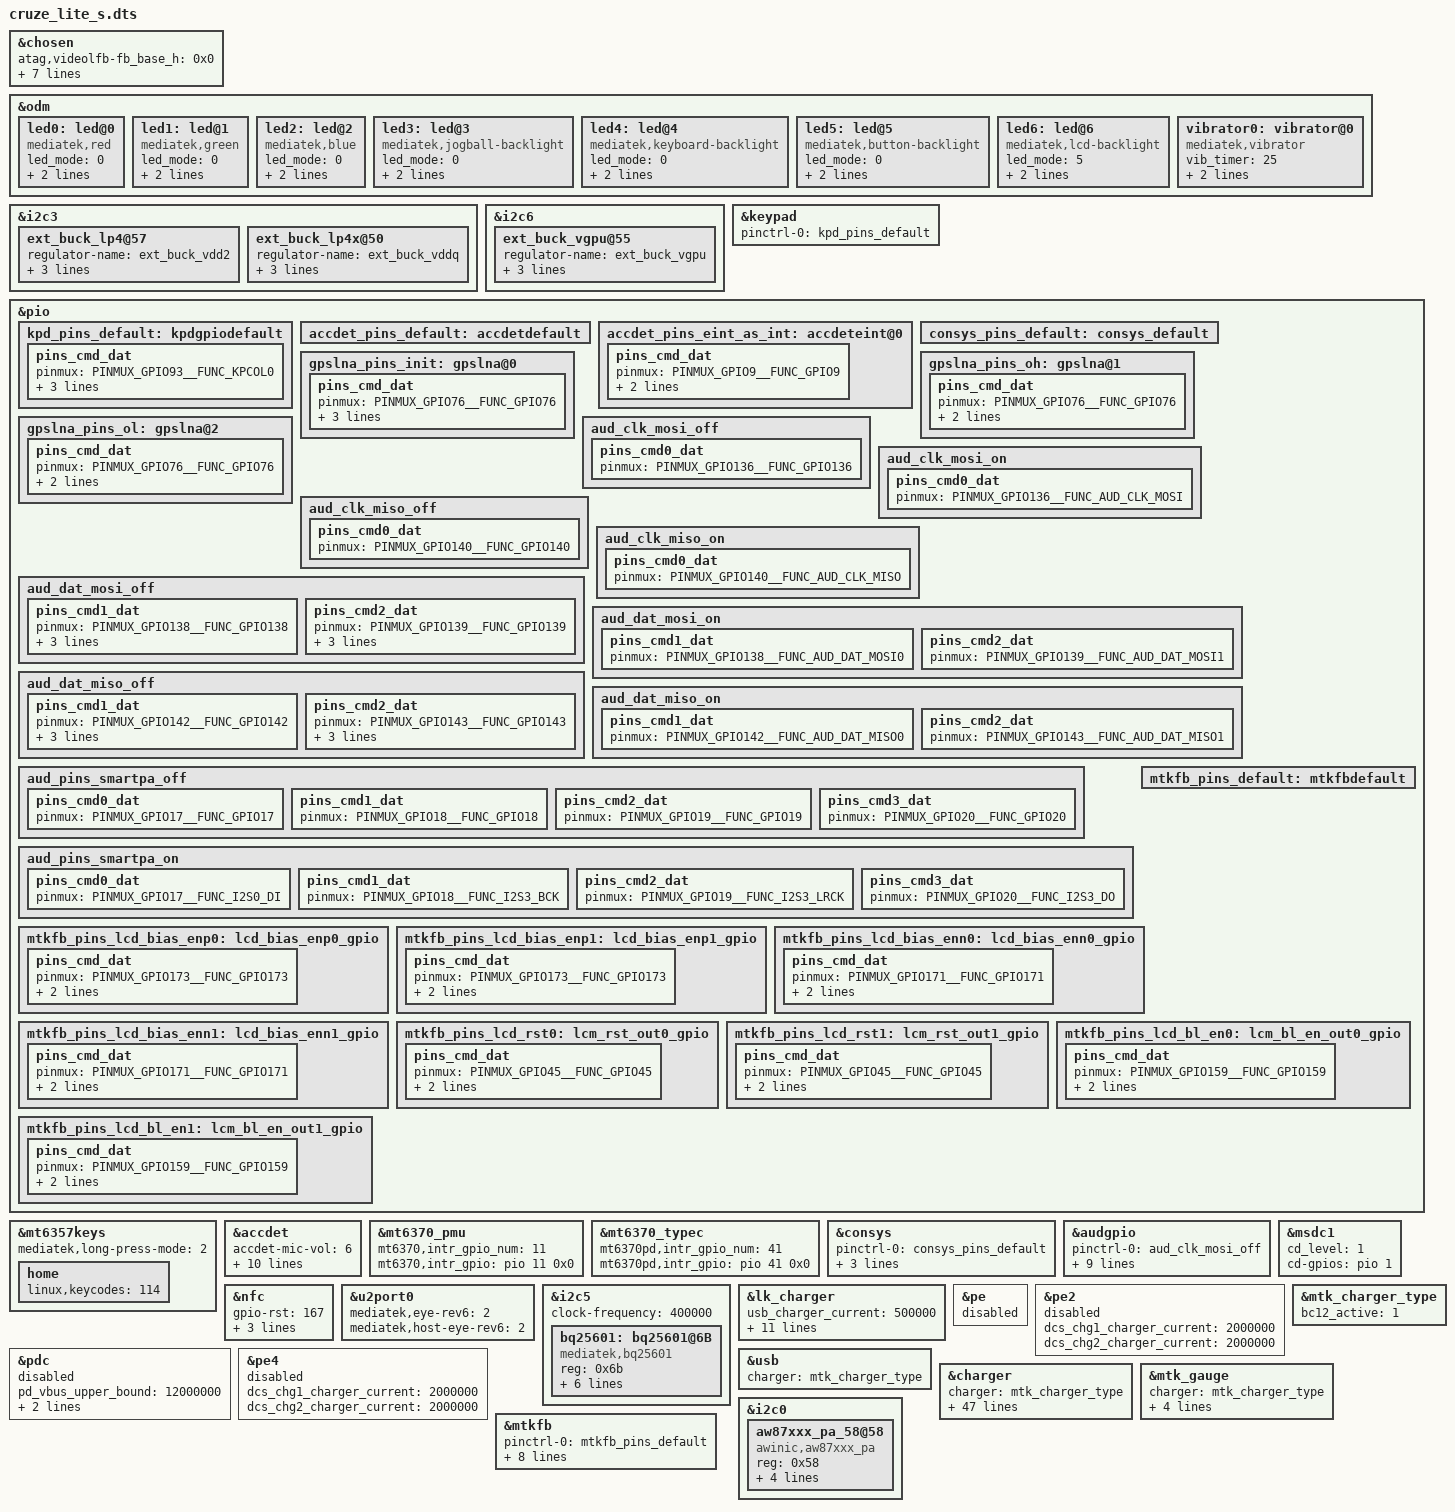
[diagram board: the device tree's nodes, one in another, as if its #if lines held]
// SPDX-License-Identifier: GPL-2.0+

#include <dt-bindings/interrupt-controller/arm-gic.h>
#include <dt-bindings/interrupt-controller/irq.h>
#include <dt-bindings/pinctrl/mt6761-pinfunc.h>
#include <dt-bindings/mmc/mt6761-msdc.h>
#include <dt-bindings/clock/mt6761-clk.h>

/dts-v1/;
/plugin/;

/* chosen */
&chosen {

	/* fpga may has no lk, we need to specify display info here */
	/* fb buffer is reserved using this dts by memory node above */
	atag,videolfb-fb_base_h = <0x0>;
	atag,videolfb-fb_base_l = <0x5e605000>;
	atag,videolfb-islcmfound = <1>;
	/* because no lk, so lcm is not inited */
	atag,videolfb-islcm_inited = <0>;
	atag,videolfb-fps= <6000>;
	atag,videolfb-vramSize= <0x017bb000>;
	atag,videolfb-lcmname= "nt35521_hd_dsi_vdo_truly_rt5081_drv";
};

&odm {
	led0:led@0 {
		compatible = "mediatek,red";
		led_mode = <0>;
		data = <1>;
		pwm_config = <0 0 0 0 0>;
	};
	led1:led@1 {
		compatible = "mediatek,green";
		led_mode = <0>;
		data = <1>;
		pwm_config = <0 0 0 0 0>;
	};
	led2:led@2 {
		compatible = "mediatek,blue";
		led_mode = <0>;
		data = <1>;
		pwm_config = <0 0 0 0 0>;
	};
	led3:led@3 {
		compatible = "mediatek,jogball-backlight";
		led_mode = <0>;
		data = <1>;
		pwm_config = <0 0 0 0 0>;
	};
	led4:led@4 {
		compatible = "mediatek,keyboard-backlight";
		led_mode = <0>;
		data = <1>;
		pwm_config = <0 0 0 0 0>;
	};
	led5:led@5 {
		compatible = "mediatek,button-backlight";
		led_mode = <0>;
		data = <1>;
		pwm_config = <0 0 0 0 0>;
	};
	led6:led@6 {
		compatible = "mediatek,lcd-backlight";
		led_mode = <5>;
		data = <1>;
		pwm_config = <0 3 0 0 0>;
	};
	vibrator0:vibrator@0 {
		compatible = "mediatek,vibrator";
		vib_timer = <25>;
		vib_limit = <9>;
		vib_vol= <9>;
	};
};

/* Begin del by jin.wang for task 11466469 at 2021-09-02 */
/* End del by jin.wang */

&i2c3 {
	ext_buck_lp4@57 {
		regulator-name ="ext_buck_vdd2";
		regulator-min-microvolt = <300000>;
		regulator-max-microvolt = <1300000>;
		vsel_pin = <0>;
	};

	ext_buck_lp4x@50 {
		regulator-name ="ext_buck_vddq";
		regulator-min-microvolt = <300000>;
		regulator-max-microvolt = <1300000>;
		vsel_pin = <1>;
	};
};

&i2c6 {
	ext_buck_vgpu@55 {
		regulator-name ="ext_buck_vgpu";
		regulator-min-microvolt = <300000>;
		regulator-max-microvolt = <1300000>;
		vsel_pin = <2>;
	};
};

&keypad {
	pinctrl-names = "default";
	pinctrl-0 = <&kpd_pins_default>;
};

&pio {
	kpd_pins_default: kpdgpiodefault {
		pins_cmd_dat {
			pinmux = <PINMUX_GPIO93__FUNC_KPCOL0>;
			bias-pull-up = <MTK_PUPD_SET_R1R0_10>;
			output-low;
			input-schmitt-enable;
		};
	};
};
/*BEGIN Add by peisong.cao for KEYCODE_VOLUME_DOWN 114*/
&mt6357keys {
#if defined(TARGET_BUILD_MMITEST) || defined(TARGET_BUILD_CERTIFICATION) || defined(TARGET_BUILD_GCF)
     mediatek,long-press-mode = <2>;
#else
     mediatek,long-press-mode = <1>;
#endif
		home {
			linux,keycodes = <114>;
		};
};
/*END Add by peisong.cao for KEYCODE_VOLUME_DOWN 114*/

&accdet {
	accdet-mic-vol = <6>;
	headset-mode-setting = <0x500 0x500 1 0x1f0 0x800 0x800 0x20 0x44>;
	accdet-plugout-debounce = <1>;
	accdet-mic-mode = <1>;
	headset-eint-level-pol = <8>;
	headset-three-key-threshold = <0 80 220 400>;
	headset-three-key-threshold-CDD = <0 121 192 600>;
	headset-four-key-threshold = <0 58 121 192 400>;
	pinctrl-names = "default", "state_eint_as_int";
	pinctrl-0 = <&accdet_pins_default>;
	pinctrl-1 = <&accdet_pins_eint_as_int>;
	status = "okay";
};
&pio {
	accdet_pins_default: accdetdefault {
	};
	accdet_pins_eint_as_int: accdeteint@0 {
		pins_cmd_dat {
			pinmux = <PINMUX_GPIO9__FUNC_GPIO9>;
			slew-rate = <0>;
			bias-disable;
		};
	};
};

&mt6370_pmu {
	mt6370,intr_gpio_num = <11>; /* direct defined GPIO num */
	mt6370,intr_gpio = <&pio 11 0x0>;
};

/* Begin del by jin.wang for task 11466469 at 2021-09-02 */

#if 0
&i2c3 {
	rt9465@4b {
		compatible = "richtek,rt9465";
		reg = <0x4b>;
		status = "okay";
		rt,en_gpio_num = <176>;
		rt,en_gpio = <&pio 176 0x0>;
		rt,intr_gpio_num = <23>; /* direct defined GPIO num */
		rt,intr_gpio = <&pio 23 0x0>;
		interrupt-names = "wdtmri";
		charger_name = "secondary_chg";
		ichg = <1500000>; /* uA */
		mivr = <4500000>; /* uV */
		cv = <4550000>; /* uV */
		ieoc = <700000>; /* uA */
		safety_timer = <12>; /* hour */
		en_st; /* safety timer */
		/* en_te; */
		en_wdt;
	};
};
#endif
/* End del by jin.wang */

&mt6370_typec {
	mt6370pd,intr_gpio_num = <41>; /* direct defined GPIO num */
	mt6370pd,intr_gpio = <&pio 41 0x0>;
};
//Begin modified by qianbo.pan for GNSS task 11475215 on 2021/08/29
/* CONSYS GPIO standardization */
&pio {
	consys_pins_default: consys_default {
	};
	gpslna_pins_init: gpslna@0 {
		pins_cmd_dat {
			pinmux = <PINMUX_GPIO76__FUNC_GPIO76>;
			slew-rate = <0>;
			bias-disable;
			output-low;
		};
	};
	gpslna_pins_oh: gpslna@1 {
		pins_cmd_dat {
			pinmux = <PINMUX_GPIO76__FUNC_GPIO76>;
			slew-rate = <1>;
			output-high;
		};
	};
	gpslna_pins_ol: gpslna@2 {
		pins_cmd_dat {
			pinmux = <PINMUX_GPIO76__FUNC_GPIO76>;
			slew-rate = <1>;
			output-low;
		};
	};
};
&consys {
	pinctrl-names = "default", "gps_lna_state_init",
		"gps_lna_state_oh", "gps_lna_state_ol";
	pinctrl-0 = <&consys_pins_default>;
	pinctrl-1 = <&gpslna_pins_init>;
	pinctrl-2 = <&gpslna_pins_oh>;
	pinctrl-3 = <&gpslna_pins_ol>;
	status = "okay";
};
/* CONSYS end */
//End modified by qianbo.pan for GNSS task 11475215 on 2021/08/29
/* AUDIO GPIO standardization */
&audgpio {
	pinctrl-names = "aud_clk_mosi_off",
			"aud_clk_mosi_on",
			"aud_clk_miso_off",
			"aud_clk_miso_on",
			"aud_dat_mosi_off",
			"aud_dat_mosi_on",
			"aud_dat_miso_off",
			"aud_dat_miso_on",
			"aud_smartpa_off",
			"aud_smartpa_on";
	pinctrl-0 = <&aud_clk_mosi_off>;
	pinctrl-1 = <&aud_clk_mosi_on>;
	pinctrl-2 = <&aud_clk_miso_off>;
	pinctrl-3 = <&aud_clk_miso_on>;
	pinctrl-4 = <&aud_dat_mosi_off>;
	pinctrl-5 = <&aud_dat_mosi_on>;
	pinctrl-6 = <&aud_dat_miso_off>;
	pinctrl-7 = <&aud_dat_miso_on>;
	pinctrl-8 = <&aud_pins_smartpa_off>;
	pinctrl-9 = <&aud_pins_smartpa_on>;
	status = "okay";
};

&pio {
	aud_clk_mosi_off: aud_clk_mosi_off {
		pins_cmd0_dat {
			pinmux = <PINMUX_GPIO136__FUNC_GPIO136>;
		};
	};

	aud_clk_mosi_on: aud_clk_mosi_on {
		pins_cmd0_dat {
			pinmux = <PINMUX_GPIO136__FUNC_AUD_CLK_MOSI>;
		};
	};

	aud_clk_miso_off: aud_clk_miso_off {
		pins_cmd0_dat {
			pinmux = <PINMUX_GPIO140__FUNC_GPIO140>;
		};
	};

	aud_clk_miso_on: aud_clk_miso_on {
		pins_cmd0_dat {
			pinmux = <PINMUX_GPIO140__FUNC_AUD_CLK_MISO>;
		};
	};

	aud_dat_mosi_off: aud_dat_mosi_off {
		pins_cmd1_dat {
			pinmux = <PINMUX_GPIO138__FUNC_GPIO138>;
			input-enable;
			slew-rate = <0>;
			bias-disable;
		};
		pins_cmd2_dat {
			pinmux = <PINMUX_GPIO139__FUNC_GPIO139>;
			input-enable;
			slew-rate = <0>;
			bias-disable;
		};
	};

	aud_dat_mosi_on: aud_dat_mosi_on {
		pins_cmd1_dat {
			pinmux = <PINMUX_GPIO138__FUNC_AUD_DAT_MOSI0>;
		};
		pins_cmd2_dat {
			pinmux = <PINMUX_GPIO139__FUNC_AUD_DAT_MOSI1>;
		};
	};

	aud_dat_miso_off: aud_dat_miso_off {
		pins_cmd1_dat {
			pinmux = <PINMUX_GPIO142__FUNC_GPIO142>;
			input-enable;
			slew-rate = <0>;
			bias-disable;
		};
		pins_cmd2_dat {
			pinmux = <PINMUX_GPIO143__FUNC_GPIO143>;
			input-enable;
			slew-rate = <0>;
			bias-disable;
		};
	};

	aud_dat_miso_on: aud_dat_miso_on {
		pins_cmd1_dat {
			pinmux = <PINMUX_GPIO142__FUNC_AUD_DAT_MISO0>;
		};
		pins_cmd2_dat {
			pinmux = <PINMUX_GPIO143__FUNC_AUD_DAT_MISO1>;
		};
	};

	aud_pins_smartpa_off: aud_pins_smartpa_off {
		pins_cmd0_dat {
			pinmux = <PINMUX_GPIO17__FUNC_GPIO17>;
		};
		pins_cmd1_dat {
			pinmux = <PINMUX_GPIO18__FUNC_GPIO18>;
		};
		pins_cmd2_dat {
			pinmux = <PINMUX_GPIO19__FUNC_GPIO19>;
		};
		pins_cmd3_dat {
			pinmux = <PINMUX_GPIO20__FUNC_GPIO20>;
		};
	};

	aud_pins_smartpa_on: aud_pins_smartpa_on {
		pins_cmd0_dat {
			pinmux = <PINMUX_GPIO17__FUNC_I2S0_DI>;
		};
		pins_cmd1_dat {
			pinmux = <PINMUX_GPIO18__FUNC_I2S3_BCK>;
		};
		pins_cmd2_dat {
			pinmux = <PINMUX_GPIO19__FUNC_I2S3_LRCK>;
		};
		pins_cmd3_dat {
			pinmux = <PINMUX_GPIO20__FUNC_I2S3_DO>;
		};
	};
};
/* AUDIO end */
/*Begin add by YuBin for sdcard det*/
&msdc1 {
       cd_level = /bits/ 8 <1>;
       cd-gpios = <&pio 1 0>;
};
/*End add by YuBin for sdcard det*/
//Begin add by na.long for task11386747 porting  on 2021/07/27
&nfc {
	gpio-rst = <167>;
	gpio-rst-std = <&pio 167 0x0>;
	gpio-irq = <9>;
	gpio-irq-std = <&pio 9 0x0>;
};
//End add by na.long for task11386747 porting  on 2021/07/27

&u2port0 {
	mediatek,eye-rev6 = <2>; /* 0~3 */
	mediatek,host-eye-rev6 = <2>; /* 0~3 */
};
/* End add by jin.wang */

/* Begin add by jin.wang for task 2064 at 2021-10-25 */
&i2c5 {
	#address-cells = <1>;
	#size-cells = <0>;
	clock-frequency = <400000>;

	bq25601:bq25601@6B {
		compatible = "mediatek,bq25601";
		reg = <0x6b>;
		id = <0x5>;
		status = "okay";
		charger_name = "primary_chg";
		alias_name = "bq25601";
		bq25601,en_gpio = <&pio 165 0x0>;
		bq25601,intr_gpio = <&pio 12 0x0>;
		eint_name = "bq25601_intr";
	};
};
/* End add by jin.wang */

/* Begin added by jin.wang for task 11466469 at 2021-09-02 */
&lk_charger {
	/* charging current */
	usb_charger_current = <500000>;
	ac_charger_current = <500000>;
	ac_charger_input_current = <500000>;
	non_std_ac_charger_current = <500000>;
	charging_host_charger_current = <500000>;
	ta_ac_charger_current = <500000>;
	pd_charger_current = <500000>;
	max_charger_voltage = <6500000>;

	/* battery temperature protection */
	temp_t4_threshold = <54>;
	temp_t3_threshold = <45>;
	temp_t1_threshold = <6>;
	temp_t0_threshold = <1>;
};

&pe {
	status = "disabled";
};

&pe2 {
	status = "disabled";
	dcs_chg1_charger_current = <2000000>;
	dcs_chg2_charger_current = <2000000>;
};

&pdc {
	status = "disabled";
	pd_vbus_upper_bound = <12000000>;
	dcs_chg1_charger_current = <2000000>;
	dcs_chg2_charger_current = <2000000>;
};

&pe4 {
	status = "disabled";
	dcs_chg1_charger_current = <2000000>;
	dcs_chg2_charger_current = <2000000>;
};

&mtk_charger_type {
	bc12_active = <1>;
};

&usb{
	charger = <&mtk_charger_type>;
};

/* Begin mod by jin.wang for jira 2064 at 2021-10-26 */
&charger {
    charger = <&mtk_charger_type>;
    charger_configuration= <0>;

    /* common */
    power_path_support;
    enable_dynamic_mivr;
    battery_cv = <4400000>;

    /* charging current */
    usb_charger_current_suspend = <0>;
    usb_charger_current_unconfigured = <70000>;
    usb_charger_current_configured = <500000>;
    usb_charger_current = <500000>;
    ac_charger_current = <2000000>;
    ac_charger_input_current = <2100000>;
    non_std_ac_charger_current = <500000>;
    charging_host_charger_current = <1300000>;

    /* sw jeita */
    enable_sw_jeita;
    jeita_temp_above_t4_cv = <4100000>;
    jeita_temp_t3_to_t4_cv = <4100000>;
    jeita_temp_t2_to_t3_cv = <4400000>;
    jeita_temp_t1_to_t2_cv = <4400000>;
    jeita_temp_t0_to_t1_cv = <4400000>;
    jeita_temp_below_t0_cv = <4400000>;
    temp_t4_thres = <55>;
    temp_t4_thres_minus_x_degree = <51>;
    temp_t3_thres = <42>;
    temp_t3_thres_minus_x_degree = <41>;
    temp_t2_thres = <11>;
    temp_t2_thres_plus_x_degree = <12>;
    temp_t1_thres = <6>;
    temp_t1_thres_plus_x_degree = <7>;
    temp_t0_thres = <0>;
    temp_t0_thres_plus_x_degree = <1>;
    temp_neg_10_thres = <2>;

    jeita_temp_above_t4_current = <0>;
    jeita_temp_t3_to_t4_current = <1500000>;
    jeita_temp_t2_to_t3_current = <3600000>;
    jeita_temp_t1_to_t2_current = <950000>;
    jeita_temp_t0_to_t1_current = <950000>;
    jeita_temp_below_t0_current = <0>;

    /* battery temperature protection */
    enable_min_charge_temp;
    min_charge_temp = <1>;
    min_charge_temp_plus_x_degree = <2>;
    max_charge_temp = <53>;
    max_charge_temp_minus_x_degree = <51>;

    enable_step_chg;
    step_chg_vbat = <4300000>;
    step_chg_vbat_hysteresis = <100000>;
    setp_chg_current = <2800000>;

    vbat_cable_imp_threshold = <3300000>; /* uV */
    car_tune_value_sy6970qcc = <1020>;
};
/* End mod by jin.wang */

#include <dt-bindings/iio/mt635x-auxadc.h>
&mtk_gauge {
	charger = <&mtk_charger_type>;
	io-channels = <&pmic_auxadc AUXADC_BAT_TEMP>,
			<&pmic_auxadc AUXADC_BATADC>,
			<&pmic_auxadc AUXADC_VBIF>,
			<&pmic_auxadc AUXADC_IMP>,
			<&auxadc 2>;
	io-channel-names = "pmic_battery_temp",
			"pmic_battery_voltage",
			"pmic_bif_voltage",
			"pmic_ptim_voltage",
			"battery_id";
};
/* End added by jin.wang */

&i2c0 {
	/* AWINIC AW87359 Smart K PA */
	aw87xxx_pa_58@58 {
		compatible = "awinic,aw87xxx_pa";
		reg = <0x58>;
		pa-channel = < 0 >;
		monitor-flag = <0>; //1=enable
		monitor-timer-val = <3000>; //time interval, ms
		monitor-timer-count-max = <5>; //counts for average
		status = "okay";
	};
	/* AWINIC AW87359 Smart K PA End */
};

/* Begin added by jin.wang for task 11466469 at 2021-09-02 */
#include "bat_setting/cruze_lite_s/cruze_lite_s_mt6761_battery_prop_ext.dtsi"
/* End added by jin.wang for task 11466469 at 2021-09-02 */

#include <cruze_lite_s/cust.dtsi>
/*Begin ersen.shang for [Task][ 11425156][cruze/cruze pro camera bring up] 202108*/
#include "cust_mt6765_camera_cruze.dtsi"
/*End   ersen.shang for [Task][ 11425156][cruze/cruze pro camera bring up] 202108*/
#include "cust_mt6761_touch_1080x1920.dtsi"
//add for lcm configure
&mtkfb {
	pinctrl-names = "default", "lcd_bias_enp0_gpio", "lcd_bias_enp1_gpio","lcd_bias_enn0_gpio", "lcd_bias_enn1_gpio",
	"lcm_rst_out0_gpio","lcm_rst_out1_gpio", "lcd_bl_en0_gpio", "lcd_bl_en1_gpio";
	pinctrl-0 = <&mtkfb_pins_default>;
	pinctrl-1 = <&mtkfb_pins_lcd_bias_enp0>;
	pinctrl-2 = <&mtkfb_pins_lcd_bias_enp1>;
	pinctrl-3 = <&mtkfb_pins_lcd_bias_enn0>;
	pinctrl-4 = <&mtkfb_pins_lcd_bias_enn1>;
	pinctrl-5 = <&mtkfb_pins_lcd_rst0>;
	pinctrl-6 = <&mtkfb_pins_lcd_rst1>;
	pinctrl-7 = <&mtkfb_pins_lcd_bl_en0>;
	pinctrl-8 = <&mtkfb_pins_lcd_bl_en1>;
	status = "okay";
};
&pio {
	mtkfb_pins_default: mtkfbdefault {
	};

	mtkfb_pins_lcd_bias_enp0: lcd_bias_enp0_gpio {
		pins_cmd_dat {
			pinmux = <PINMUX_GPIO173__FUNC_GPIO173>;
			slew-rate = <1>;
			output-low;
		};
	};
	mtkfb_pins_lcd_bias_enp1: lcd_bias_enp1_gpio {
		pins_cmd_dat {
			pinmux = <PINMUX_GPIO173__FUNC_GPIO173>;
			slew-rate = <1>;
			output-high;
		};
	};
	mtkfb_pins_lcd_bias_enn0: lcd_bias_enn0_gpio {
		pins_cmd_dat {
				pinmux = <PINMUX_GPIO171__FUNC_GPIO171>;
				slew-rate = <1>;
				output-low;
		};
    };
    mtkfb_pins_lcd_bias_enn1: lcd_bias_enn1_gpio {
        pins_cmd_dat {
            pinmux = <PINMUX_GPIO171__FUNC_GPIO171>;
            slew-rate = <1>;
            output-high;
		};
	};

	mtkfb_pins_lcd_rst0: lcm_rst_out0_gpio {
		pins_cmd_dat {
			pinmux = <PINMUX_GPIO45__FUNC_GPIO45>;
			slew-rate = <1>;
			output-low;
		};
	};

	mtkfb_pins_lcd_rst1: lcm_rst_out1_gpio {
		pins_cmd_dat {
			pinmux = <PINMUX_GPIO45__FUNC_GPIO45>;
			slew-rate = <1>;
			output-high;
		};
	};
	mtkfb_pins_lcd_bl_en0: lcm_bl_en_out0_gpio {
		pins_cmd_dat {
			pinmux = <PINMUX_GPIO159__FUNC_GPIO159>;
			slew-rate = <1>;
			output-low;
		};
	};

	mtkfb_pins_lcd_bl_en1: lcm_bl_en_out1_gpio {
		pins_cmd_dat {
			pinmux = <PINMUX_GPIO159__FUNC_GPIO159>;
			slew-rate = <1>;
			output-high;
		};
	};
};
#include "cruze_pro_tp_ft8756.dtsi"
#include "cruze_lite-fpsensor.dtsi"
/*End of this file, DO NOT ADD ANYTHING HERE*/
